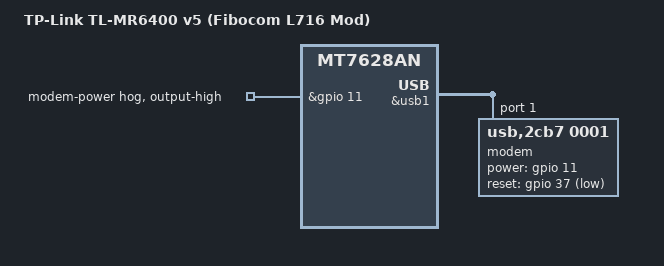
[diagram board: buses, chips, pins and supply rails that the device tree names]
/dts-v1/;

#include "mt7628an_tplink_tl-mr6400-v5.dts" // Hanya sekali dan pastikan file yang dimasukkan benar

/ {
    model = "TP-Link TL-MR6400 v5 (Fibocom L716 Mod)";
    compatible = "tplink,tl-mr6400-v5-fibocom", "tplink,tl-mr6400-v5", "mediatek,mt7628an-soc";

    aliases {
        led-boot = &led_power;
        led-failsafe = &led_power;
        led-running = &led_power;
        led-upgrade = &led_power;
    };

    chosen {
        bootargs = "console=ttyS0,115200";
    };

    usb_modem: fibocom-l716 {
        compatible = "fibocom,l716";
        status = "okay";
    };
&usb1 {
	status = "okay";

	modem@1 {
		compatible = "usb,2cb7,0001";
		reg = <1>;
		power-gpios = <&gpio 11 GPIO_ACTIVE_HIGH>;
		reset-gpios = <&gpio 37 GPIO_ACTIVE_LOW>;
	};
};

&gpio {
	modem_power {
		gpio-hog;
		gpios = <11 GPIO_ACTIVE_HIGH>;
		output-high;
		line-name = "modem-power";
	};
};
};
